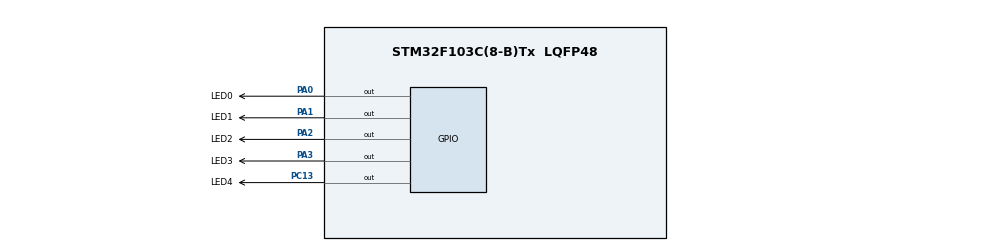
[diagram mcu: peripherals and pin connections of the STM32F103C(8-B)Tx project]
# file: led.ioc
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Mcu.Family=STM32F1
Mcu.Name=STM32F103C(8-B)Tx
Mcu.Package=LQFP48
NVIC.PriorityGroup=NVIC_PRIORITYGROUP_4
NVIC.TIM4_IRQn=true\:0\:0\:false\:false\:true\:true\:true\:true
PA0-WKUP.GPIO_Label=LED0
PA0-WKUP.Signal=GPIO_Output
PA1.GPIO_Label=LED1
PA1.Signal=GPIO_Output
PA2.GPIO_Label=LED2
PA2.Signal=GPIO_Output
PA3.GPIO_Label=LED3
PA3.Signal=GPIO_Output
PC13-TAMPER-RTC.GPIO_Label=LED4
PC13-TAMPER-RTC.Signal=GPIO_Output
PC14-OSC32_IN.Mode=LSE-External-Oscillator
PC14-OSC32_IN.Signal=RCC_OSC32_IN
PC15-OSC32_OUT.Mode=LSE-External-Oscillator
PC15-OSC32_OUT.Signal=RCC_OSC32_OUT
PD0-OSC_IN.Mode=HSE-External-Oscillator
PD0-OSC_IN.Signal=RCC_OSC_IN
PD1-OSC_OUT.Mode=HSE-External-Oscillator
PD1-OSC_OUT.Signal=RCC_OSC_OUT
ProjectManager.HeapSize=0x200
ProjectManager.StackSize=0x400
ProjectManager.TargetToolchain=Makefile
RCC.APB1Freq_Value=8000000
RCC.APB2Freq_Value=8000000
RCC.SYSCLKSource=RCC_SYSCLKSOURCE_HSE
TIM4.AutoReloadPreload=TIM_AUTORELOAD_PRELOAD_DISABLE
TIM4.Period=4000
TIM4.Prescaler=0
VP_SYS_VS_ND.Mode=No_Debug
VP_TIM4_VS_ClockSourceINT.Mode=Internal
board=custom

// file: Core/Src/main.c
/* USER CODE BEGIN Header */
/**
 ******************************************************************************
 * @file           : main.c
 * @brief          : Main program body
 ******************************************************************************
 * @attention
 *
 * Copyright (c) 2022 STMicroelectronics.
 * All rights reserved.
 *
 * This software is licensed under terms that can be found in the LICENSE file
 * in the root directory of this software component.
 * If no LICENSE file comes with this software, it is provided AS-IS.
 *
 ******************************************************************************
 */
/* USER CODE END Header */
#include "main.h"

TIM_HandleTypeDef htim4;

void SystemClock_Config(void);
static void MX_GPIO_Init(void);
static void MX_TIM4_Init(void);

int main(void)
{

  /* MCU Configuration--------------------------------------------------------*/

  /* Reset of all peripherals, Initializes the Flash interface and the Systick. */
  HAL_Init();

  /* Configure the system clock */
  SystemClock_Config();

  /* Initialize all configured peripherals */
  MX_GPIO_Init();
  MX_TIM4_Init();
  /* USER CODE BEGIN 2 */
  HAL_TIM_Base_Start_IT(&htim4);
  /* USER CODE END 2 */

  /* Infinite loop */
  /* USER CODE BEGIN WHILE */
  while (1) {
    __WFI();
    /* USER CODE END WHILE */

  }
}

void SystemClock_Config(void)
{
  RCC_OscInitTypeDef RCC_OscInitStruct = {0};
  RCC_ClkInitTypeDef RCC_ClkInitStruct = {0};

  /** Initializes the RCC Oscillators according to the specified parameters
  * in the RCC_OscInitTypeDef structure.
  */
  RCC_OscInitStruct.OscillatorType = RCC_OSCILLATORTYPE_HSE;
  RCC_OscInitStruct.HSEState = RCC_HSE_ON;
  RCC_OscInitStruct.PLL.PLLState = RCC_PLL_NONE;
  if (HAL_RCC_OscConfig(&RCC_OscInitStruct) != HAL_OK)
  {
    Error_Handler();
  }

  /** Initializes the CPU, AHB and APB buses clocks
  */
  RCC_ClkInitStruct.ClockType = RCC_CLOCKTYPE_HCLK|RCC_CLOCKTYPE_SYSCLK
                              |RCC_CLOCKTYPE_PCLK1|RCC_CLOCKTYPE_PCLK2;
  RCC_ClkInitStruct.SYSCLKSource = RCC_SYSCLKSOURCE_HSE;
  RCC_ClkInitStruct.AHBCLKDivider = RCC_SYSCLK_DIV1;
  RCC_ClkInitStruct.APB1CLKDivider = RCC_HCLK_DIV1;
  RCC_ClkInitStruct.APB2CLKDivider = RCC_HCLK_DIV1;

  if (HAL_RCC_ClockConfig(&RCC_ClkInitStruct, FLASH_LATENCY_0) != HAL_OK)
  {
    Error_Handler();
  }
}

static void MX_TIM4_Init(void)
{

  TIM_ClockConfigTypeDef sClockSourceConfig = {0};
  TIM_MasterConfigTypeDef sMasterConfig = {0};

  htim4.Instance = TIM4;
  htim4.Init.Prescaler = 0;
  htim4.Init.CounterMode = TIM_COUNTERMODE_UP;
  htim4.Init.Period = 4000;
  htim4.Init.ClockDivision = TIM_CLOCKDIVISION_DIV1;
  htim4.Init.AutoReloadPreload = TIM_AUTORELOAD_PRELOAD_DISABLE;
  if (HAL_TIM_Base_Init(&htim4) != HAL_OK)
  {
    Error_Handler();
  }
  sClockSourceConfig.ClockSource = TIM_CLOCKSOURCE_INTERNAL;
  if (HAL_TIM_ConfigClockSource(&htim4, &sClockSourceConfig) != HAL_OK)
  {
    Error_Handler();
  }
  sMasterConfig.MasterOutputTrigger = TIM_TRGO_RESET;
  sMasterConfig.MasterSlaveMode = TIM_MASTERSLAVEMODE_DISABLE;
  if (HAL_TIMEx_MasterConfigSynchronization(&htim4, &sMasterConfig) != HAL_OK)
  {
    Error_Handler();
  }

}

static void MX_GPIO_Init(void)
{
  GPIO_InitTypeDef GPIO_InitStruct = {0};

  /* GPIO Ports Clock Enable */
  __HAL_RCC_GPIOC_CLK_ENABLE();
  __HAL_RCC_GPIOD_CLK_ENABLE();
  __HAL_RCC_GPIOA_CLK_ENABLE();

  /*Configure GPIO pin Output Level */
  HAL_GPIO_WritePin(LED4_GPIO_Port, LED4_Pin, GPIO_PIN_RESET);

  /*Configure GPIO pin Output Level */
  HAL_GPIO_WritePin(GPIOA, LED0_Pin|LED1_Pin|LED2_Pin|LED3_Pin, GPIO_PIN_RESET);

  /*Configure GPIO pin : LED4_Pin */
  GPIO_InitStruct.Pin = LED4_Pin;
  GPIO_InitStruct.Mode = GPIO_MODE_OUTPUT_PP;
  GPIO_InitStruct.Pull = GPIO_NOPULL;
  GPIO_InitStruct.Speed = GPIO_SPEED_FREQ_LOW;
  HAL_GPIO_Init(LED4_GPIO_Port, &GPIO_InitStruct);

  /*Configure GPIO pins : LED0_Pin LED1_Pin LED2_Pin LED3_Pin */
  GPIO_InitStruct.Pin = LED0_Pin|LED1_Pin|LED2_Pin|LED3_Pin;
  GPIO_InitStruct.Mode = GPIO_MODE_OUTPUT_PP;
  GPIO_InitStruct.Pull = GPIO_NOPULL;
  GPIO_InitStruct.Speed = GPIO_SPEED_FREQ_LOW;
  HAL_GPIO_Init(GPIOA, &GPIO_InitStruct);

}

void Error_Handler(void)
{
  __disable_irq();
  while (1) {
  }
}

#ifdef  USE_FULL_ASSERT
/**
  * @brief  Reports the name of the source file and the source line number
  *         where the assert_param error has occurred.
  * @param  file: pointer to the source file name
  * @param  line: assert_param error line source number
  * @retval None
  */
void assert_failed(uint8_t *file, uint32_t line)
{
  /* USER CODE BEGIN 6 */
  /* User can add his own implementation to report the file name and line
     number, ex: printf("Wrong parameters value: file %s on line %d\r\n", file,
     line) */
  /* USER CODE END 6 */
}
#endif /* USE_FULL_ASSERT */
